# DISPC register map
Vendor: Texas Instruments
Peripheral module from a debugger description file (folder omap5430_ES2_PUBLIC).
Registers are 32-bit, access per field, reset 0x0 unless marked. A register's access mark holds for its fields unless they carry their own. Offsets are as the file gives them; lines under a group give offsets from that group; [hi:lo] are bit positions; {n}, {i} and the like mark numbered series; 'fields as' and 'values as' point back to an identical list; <NAME> marks a mode.

## DISPC (part 1 of 7)
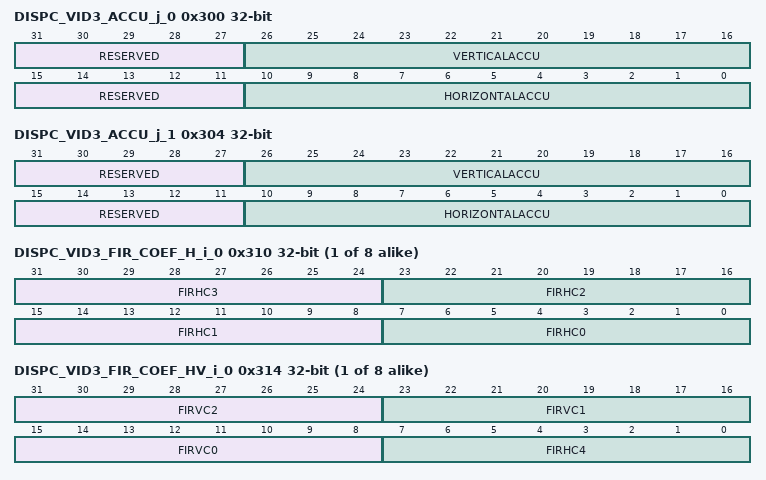
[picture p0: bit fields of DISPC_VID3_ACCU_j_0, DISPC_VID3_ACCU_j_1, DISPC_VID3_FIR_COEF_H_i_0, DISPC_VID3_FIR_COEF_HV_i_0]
0x300 DISPC_VID3_ACCU_j_0 — The register configures the resize accumulator init values for horizontal and vertical up/downsampling of the video window 3 (DISPC_VID3_ACCU_0 and DISPC_VID3_ACCU_1 for ping-pong mechanism with external trigger, based on the field polarity). It is used for ARGB and Y setting. Shadow register, updated on VFP start period of primary LCD or VFP start period of the secondary LCD or VFP start period of the third LCD or EVSYNC or when.GOWB is set to 1 by software and current WB frame is finished (no more data in the write-back pipeline). The synchronization event is defined based on the output using the pipeline: primary LCD, secondary LCD, third LCD, TV output or write-back to the memory
  [31:27] RESERVED ro — Write 0s for future compatibility. Reads return 0.
  [26:16] VERTICALACCU rw — Vertical initialization accu value Encoded value (from –1024 to 1023).
  [15:11] RESERVED ro — Write 0s for future compatibility. Reads return 0.
  [10:0] HORIZONTALACCU rw — Horizontal initialization accu value Encoded value (from –1024 to 1023).
0x304 DISPC_VID3_ACCU_j_1 — The register configures the resize accumulator init values for horizontal and vertical up/downsampling of the video window 3 (DISPC_VID3_ACCU_0 and DISPC_VID3_ACCU_1 for ping-pong mechanism with external trigger, based on the field polarity). It is used for ARGB and Y setting. Shadow register, updated on VFP start period of primary LCD or VFP start period of the secondary LCD or VFP start period of the third LCD or EVSYNC or when.GOWB is set to 1 by software and current WB frame is finished (no more data in the write-back pipeline). The synchronization event is defined based on the output using the pipeline: primary LCD, secondary LCD, third LCD, TV output or write-back to the memory
  fields as DISPC_VID3_ACCU_j_0
0x308 DISPC_VID3_BA_j_0 rw — The register configures the base address of the video buffer for the video window 3 (DISPC_VID3_BA_0 and DISPC_VID3_BA_1 for ping-pong mechanism with external trigger, based on the field polarity otherwise only DISPC_VID3_BA_0 is used)). Shadow register, updated on VFP start period of primary LCD or VFP start period of the secondary LCD or VFP start period of the third LCD or EVSYNC or when.GOWB is set to 1 by software and current WB frame is finished (no more data in the write-back pipeline). The synchronization event is defined based on the output using the pipeline: primary LCD, secondary LCD, third LCD, TV output or write-back to the memory
  [31:0] BA — Video base address Base address of the video buffer (aligned on pixel size boundary except in case of RGB24 packed format, 4-pixel alignment is required; in case of YUV4:2:2, 2-pixel alignment is required, and YUV4:2:0, byte alignment is supported)). It case of YUV4:2:0 format, it indicates the base address of the Y buffer. When the TILER is addressed, the bits: [28:27] = 0x0 for 8-bit tiled [28:27] = 0x1 for 16-bit tiled [28:27] = 0x2 for 32-bit tiled [28:27] = 0x3 for page mode [31:29] = 0x0 for 0-degree view [31:29] = 0x1 for 180-degree view + mirroring [31:29] = 0x2 for 0-degree view + mirroring [31:29] = 0x3 for 180-degree view [31:29] = 0x4 for 270-degree view + mirroring [31:29] = 0x5 for 270-degree view [31:29] = 0x6 for 90-degree view [31:29] = 0x7 for 90-degree view + mirroring Otherwise the bits indicated the corresponding bit address to access the SDRAM.
0x30C DISPC_VID3_BA_j_1 rw — The register configures the base address of the video buffer for the video window 3 (DISPC_VID3_BA_0 and DISPC_VID3_BA_1 for ping-pong mechanism with external trigger, based on the field polarity otherwise only DISPC_VID3_BA_0 is used)). Shadow register, updated on VFP start period of primary LCD or VFP start period of the secondary LCD or VFP start period of the third LCD or EVSYNC or when.GOWB is set to 1 by software and current WB frame is finished (no more data in the write-back pipeline). The synchronization event is defined based on the output using the pipeline: primary LCD, secondary LCD, third LCD, TV output or write-back to the memory
  fields as DISPC_VID3_BA_j_0
{0x310+8i} DISPC_VID3_FIR_COEF_H_i_{i} rw (i=0..7) — The bank of registers configure the up/down-scaling coefficients for the horizontal resize of the video picture associated with the video window 3 for the phases from 0 to 7. It is used for ARGB and Y setting. Shadow register, updated on VFP start period of primary LCD or VFP start period of the secondary LCD or VFP start period of the third LCD or EVSYNC or when.GOWB is set to 1 by software and current WB frame is finished (no more data in the write-back pipeline). The synchronization event is defined based on the output using the pipeline: primary LCD, secondary LCD, third LCD, TV output or write-back to the memory
  [31:24] FIRHC3 — Signed coefficient C3 for the horizontal up/down-scaling with the phase n
  [23:16] FIRHC2 — Unsigned coefficient C2 for the horizontal up/down-scaling with the phase n
  [15:8] FIRHC1 — Signed coefficient C1 for the horizontal up/down-scaling with the phase n
  [7:0] FIRHC0 — Signed coefficient C0 for the horizontal up/down-scaling with the phase n
{0x314+8i} DISPC_VID3_FIR_COEF_HV_i_{i} rw (i=0..7) — The bank of registers configure the down/up/down-scaling coefficients for the vertical and horizontal resize of the video picture associated with the video window 3 for the phases from 0 to 7. It is used for ARGB and Y setting. Shadow register, updated on VFP start period of primary LCD or VFP start period of the secondary LCD or VFP start period of the third LCD or EVSYNC or when.GOWB is set to 1 by software and current WB frame is finished (no more data in the write-back pipeline). The synchronization event is defined based on the output using the pipeline: primary LCD, secondary LCD, third LCD, TV output or write-back to the memory
  [31:24] FIRVC2 — Signed coefficient C2 for the vertical up/down-scaling with the phase n
  [23:16] FIRVC1 — Unsigned coefficient C1 for the vertical up/down-scaling with the phase n
  [15:8] FIRVC0 — Signed coefficient C0 for the vertical up/down-scaling with the phase n
  [7:0] FIRHC4 — Signed coefficient C4 for the horizontal up/down-scaling with the phase n
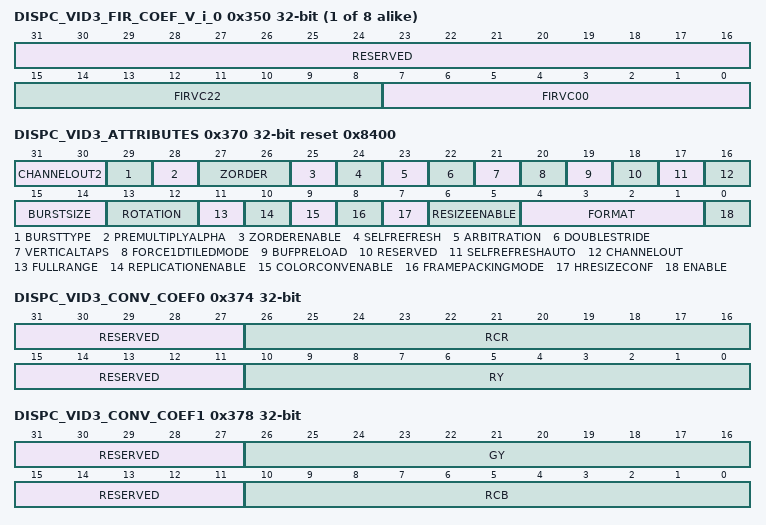
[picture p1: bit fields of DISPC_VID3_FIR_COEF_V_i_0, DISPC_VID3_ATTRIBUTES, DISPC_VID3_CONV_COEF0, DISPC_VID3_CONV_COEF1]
{0x350+4i} DISPC_VID3_FIR_COEF_V_i_{i} (i=0..7) — The bank of registers configure the down/up/down-scaling coefficients for the vertical resize of the video picture associated with the video window 3 for the phases from 0 to 7. It is used for ARGB and Y setting. Shadow register, updated on VFP start period of primary LCD or VFP start period of the secondary LCD or VFP start period of the third LCD or EVSYNC or when.GOWB is set to 1 by software and current WB frame is finished (no more data in the write-back pipeline). The synchronization event is defined based on the output using the pipeline: primary LCD, secondary LCD, third LCD, TV output or write-back to the memory
  [31:16] RESERVED ro — Write 0s for future compatibility. Reads return 0.
  [15:8] FIRVC22 rw — Signed coefficient C22 for the vertical up/down-scaling with the phase n
  [7:0] FIRVC00 rw — Signed coefficient C00 for the vertical up/down-scaling with the phase n
0x370 DISPC_VID3_ATTRIBUTES reset 0x8400 — The register configures the attributes of the video window 3. Shadow register, updated on VFP start period of primary LCD or VFP start period of the secondary LCD or VFP start period of the third LCD or EVSYNC or when.GOWB is set to 1 by software and current WB frame is finished (no more data in the write-back pipeline). The synchronization event is defined based on the output using the pipeline: primary LCD, secondary LCD, third LCD, TV output or write-back to the memory
  [31:30] CHANNELOUT2 rw — It is not used if CHANNELOUT is set to TV. Reserved when CHANNELOUT = 1 (should be set to zero) wr: immediate
    0=PrimaryLCDSel (Primary LCD output selected.); 1=SecondaryLCDSel (Secondary LCD output selected.); 2=ThirdLCDSel (Third LCD output selected.); 3=WriteBacksel (Write-back output to the memory selected.)
  [29] BURSTTYPE rw — The type of burst can be INCR (incremental) or BLCK (2D block). The 2D block is required when the TILER is targeted by the DMA engine.
    0=INC (INC burst type is used.); 1=BLCK (2D block burst type is used.)
  [28] PREMULTIPLYALPHA rw — The field configures the DISPC VID3 to process incoming data as premultiplied alpha data or non premultiplied alpha data. Default setting is non premultiplied alpha data.
    0=PremultipliedAlpha (Non premultiplyalpha data color component); 1=PremultipliedAlpha (Premultiplyalpha data color component)
  [27:26] ZORDER rw — Z-Order defining the priority of the layer compared to others when overlaying. It is software responsibility to ensure that each layer connected to the same overlay manager has a different z-order value. If bit 25 is set to 0, the ZORDER bit field is ignored and replaced by the value 0.
    0=Z-order 0: layer above solid background color and below layer with higher Z-order values; 1=Z-order 1: layer above layer with z-order value of 0 and below layers with z-order values of 2 and 3; 3=Z-order 3: layer above all the other layers; 2=Z-order 2: layer above layers with z-order value of 0 and 1 and below layer with z-order value of 3
  [25] ZORDERENABLE rw — Z-order Enable. The bit field ZORDER is used only when the Z-order is enabled.
    0=Z-order disabled. The Z-order of the layer is 0.; 1=ZorderEnb (Z-order enabled. The Z-order is defined by the bit field ZORDER (bits 26 and 27).)
  [24] SELFREFRESH rw — Enables the self refresh of the video window from its own DMA buffer only.
    0=SelfRefreshDis (The video pipeline accesses the interconnect to fetch data from the system memory.); 1=SelfRefreshEnb (The video pipeline does not need anymore to fetch data from memory. Only the DMA buffer associated with the video3 is used. It takes effect after the frame has been loaded in the DMA buffer.)
  [23] ARBITRATION rw — Determines the priority of the video pipeline. The video pipeline is one of the high priority pipeline. The arbitration gives always the priority first to the high priority pipelines using round-robin between them. When there is only normal priority pipelines sending requests, the round-robin applies between them.
    0=NormalPrio (The video pipeline is one of the normal priority pipeline.); 1=HighPrio (The video pipeline is one of the high priority pipeline.)
  [22] DOUBLESTRIDE rw — Determines if the stride for CbCr buffer is the 1x or 2x of the Y buffer stride. It is only used in case of YUV4:2:0.
    0=Initial (The CbCr stride value is equal to the Y stride.); 1=Double (The CbCr stride value is double to the Y stride.)
  [21] VERTICALTAPS rw — Video vertical resize tap number
    0=taps3 (3 taps are used for the vertical filtering logic. The 2 other taps are not used. The associated bit fields for the 2 other taps coefficients do not need to be initialized.); 1=taps5 (5 taps are used for the vertical filtering logic.)
  [20] FORCE1DTILEDMODE rw — Force TILED regions access to 1D or 2D.
    0=TiledRegions2DAccess (2D accesses for tiled regions); 1=TiledRegions1DAccess (1D accesses for tiled regions)
  [19] BUFPRELOAD rw — Video Preload Value
    0=DefVal (Hardware prefetches pixels up to the preload value defined in the preload register); 1=HighThres (Hardware prefetches pixels up to high threshold value)
  [18] RESERVED ro — Write 0s for future compatibility. Reads return 0.
  [17] SELFREFRESHAUTO rw — Automatic self-refresh mode
    0=SelfRefreshAutoDis (The transition from SELFREFRESH disabled to enabled is controlled by SW.); 1=SelfrefreshAutoEn (The transition from SELFREFRESH disabled to enabled is controlled only by hardware.)
  [16] CHANNELOUT rw — Video channel out configuration: LCD, WB or TV. wr: immediate
    0=LCDOp (LCD output or WB to the memory selected. bit fields 31 and 30 defines the output associated (primary, secondary or write-back).); 1=TVOp (TV output selected)
  [15:14] BURSTSIZE rw — Video DMA burst size
    0=Burst2x128b (2 × 128-bit bursts); 1=Burst4x128b (4 × 128-bit bursts); 2=Burst8x128b (8 × 128-bit bursts)
  [13:12] ROTATION rw — Video rotation flag
    0=No rotation; 1=Rot90 (Rotation by 90 degrees); 3=Rot270 (Rotation by 270 degrees); 2=Rot180 (Rotation by 180 degrees)
  [11] FULLRANGE rw — Color Space Conversion full range setting.
    0=Limrange (Limited range selected: 16 subtracted from Y before color space conversion); 1=Full range selected: Y is not modified before the color space conversion
  [10] REPLICATIONENABLE rw
    0=VRepLDis (Disable Video replication logic); 1=VRepLEnb (Enable Video replication logic)
  [9] COLORCONVENABLE rw — Enable the color space conversion. The hardware does not enable/disable the conversion based on the pixel format. The bit field shall be reset when the format is not YUV.
    0=ColSpCDis (Disable Color Space Conversion YUV to RGB); 1=ColSpCEnb (Enable Color Space Conversion YUV to RGB)
  [8] FRAMEPACKINGMODE rw — Frame packing mode control.
    0=FPMDis (Frame Packing mode is disabled); 1=FPMEnb (Nibble mode is enabled)
  [7] HRESIZECONF ro — Write 0s for future compatibility. Reads return 0.
  [6:5] RESIZEENABLE rw — Video resize enable
    0=ReSizeProc (Disable both horizontal and vertical resize processing); 1=HReSize (Enable the horizontal resize processing); 3=HVReSize (Enable both horizontal and vertical resize processing); 2=VReSize (Enable the vertical resize processing)
  [4:1] FORMAT rw — Video format. It defines the pixel format when fetching the video 3 picture into memory.
    6=RGB16 (RGB16-565); 1=RGBx12 (RGB12x-4444); 10=YUV2 (YUV2 4:2:2 co-sited); 7=ARGB16_1 (ARGB16-1555); 13=RGBA32 (RGBA32-8888); 0=NV12 (NV12 4:2:0 2 buffers (Y + UV)); 2=RGBA12 (RGBA12-4444); 8=xRGB24 (RGB24-8888 (32-bit container)); 9=RGB24 (RGB24-888 (24-bit container)); 11=UYVY (UYVY 4:2:2 co-sited); 5=ARGB16 (ARGB16-4444); 15=xRGB15-1555; 12=ARGB32 (ARGB32-8888); 4=xRGB12-4444; 3=BGRA32 (BGRA32-8888); 14=xRGB12 (RGBx24-8888 (24-bit RGB aligned on MSB of the 32-bit container))
  [0] ENABLE rw — Video Enable
    0=Video disabled (video pipeline inactive and window not present); 1=VideoEnb (Video enabled (video pipeline active and window present on the screen))
0x374 DISPC_VID3_CONV_COEF0 — The register configures the color space conversion matrix coefficients for the video pipeline 3. Shadow register, updated on VFP start period of primary LCD or VFP start period of the secondary LCD or VFP start period of the third LCD or EVSYNC or when.GOWB is set to 1 by software and current WB frame is finished (no more data in the write-back pipeline). The synchronization event is defined based on the output using the pipeline: primary LCD, secondary LCD, third LCD, TV output or write-back to the memory
  [31:27] RESERVED ro — Write 0s for future compatibility. Reads return 0.
  [26:16] RCR rw — RCr coefficient encoded signed value (from –1024 to 1023).
  [15:11] RESERVED ro — Write 0s for future compatibility. Reads return 0.
  [10:0] RY rw — RY coefficient encoded signed value (from –1024 to 1023).
0x378 DISPC_VID3_CONV_COEF1 — The register configures the color space conversion matrix coefficients for the video pipeline 3. Shadow register, updated on VFP start period of primary LCD or VFP start period of the secondary LCD or VFP start period of the third LCD or EVSYNC or when.GOWB is set to 1 by software and current WB frame is finished (no more data in the write-back pipeline). The synchronization event is defined based on the output using the pipeline: primary LCD, secondary LCD, third LCD, TV output or write-back to the memory
  [31:27] RESERVED ro — Write 0s for future compatibility. Reads return 0.
  [26:16] GY rw — GY coefficient encoded signed value (from –1024 to 1023).
  [15:11] RESERVED ro — Write 0s for future compatibility. Reads return 0.
  [10:0] RCB rw — RCb coefficient encoded signed value (from –1024 to 1023).
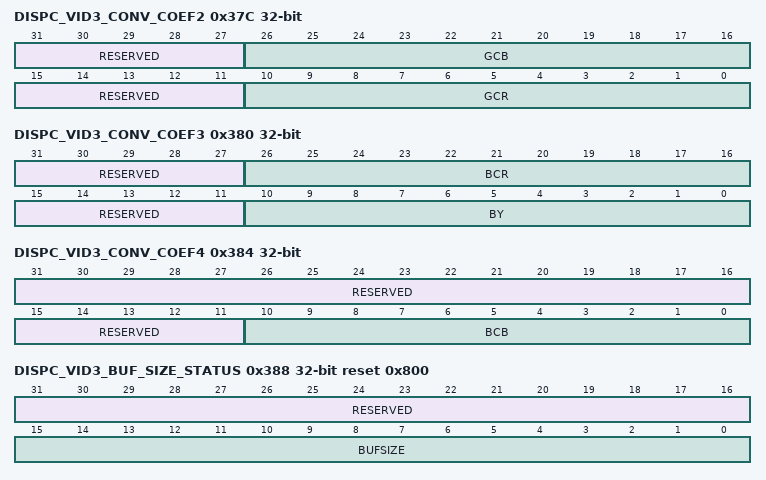
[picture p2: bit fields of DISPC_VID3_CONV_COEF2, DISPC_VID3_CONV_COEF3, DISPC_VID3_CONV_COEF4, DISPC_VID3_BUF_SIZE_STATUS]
0x37C DISPC_VID3_CONV_COEF2 — The register configures the color space conversion matrix coefficients for the video pipeline 3. Shadow register, updated on VFP start period of primary LCD or VFP start period of the secondary LCD or VFP start period of the third LCD or EVSYNC or when.GOWB is set to 1 by software and current WB frame is finished (no more data in the write-back pipeline). The synchronization event is defined based on the output using the pipeline: primary LCD, secondary LCD, third LCD, TV output or write-back to the memory
  [31:27] RESERVED ro — Write 0s for future compatibility. Reads return 0.
  [26:16] GCB rw — GCb coefficient encoded signed value (from –1024 to 1023).
  [15:11] RESERVED ro — Write 0s for future compatibility. Reads return 0.
  [10:0] GCR rw — GCr coefficient encoded signed value (from –1024 to 1023).
0x380 DISPC_VID3_CONV_COEF3 — The register configures the color space conversion matrix coefficients for the video pipeline 3. Shadow register, updated on VFP start period of primary LCD or VFP start period of the secondary LCD or VFP start period of the third LCD or EVSYNC or when.GOWB is set to 1 by software and current WB frame is finished (no more data in the write-back pipeline). The synchronization event is defined based on the output using the pipeline: primary LCD, secondary LCD, third LCD, TV output or write-back to the memory
  [31:27] RESERVED ro — Write 0s for future compatibility. Reads return 0.
  [26:16] BCR rw — BCr coefficient encoded signed value (from –1024 to 1023).
  [15:11] RESERVED ro — Write 0s for future compatibility. Reads return 0.
  [10:0] BY rw — BY coefficient encoded signed value (from –1024 to 1023).
0x384 DISPC_VID3_CONV_COEF4 — The register configures the color space conversion matrix coefficients for the video pipeline 3. Shadow register, updated on VFP start period of primary LCD or VFP start period of the secondary LCD or VFP start period of the third LCD or EVSYNC or when.GOWB is set to 1 by software and current WB frame is finished (no more data in the write-back pipeline). The synchronization event is defined based on the output using the pipeline: primary LCD, secondary LCD, third LCD, TV output or write-back to the memory
  [31:11] RESERVED ro — Write 0s for future compatibility. Reads return 0.
  [10:0] BCB rw — BCb coefficient encoded signed value (from –1024 to 1023).
0x388 DISPC_VID3_BUF_SIZE_STATUS ro reset 0x800 — The register defines the DMA buffer size for the video pipeline 3.
  [31:16] RESERVED — Write 0s for future compatibility. Reads return 0.
  [15:0] BUFSIZE — DMA buffer Size in number of 128 bits.
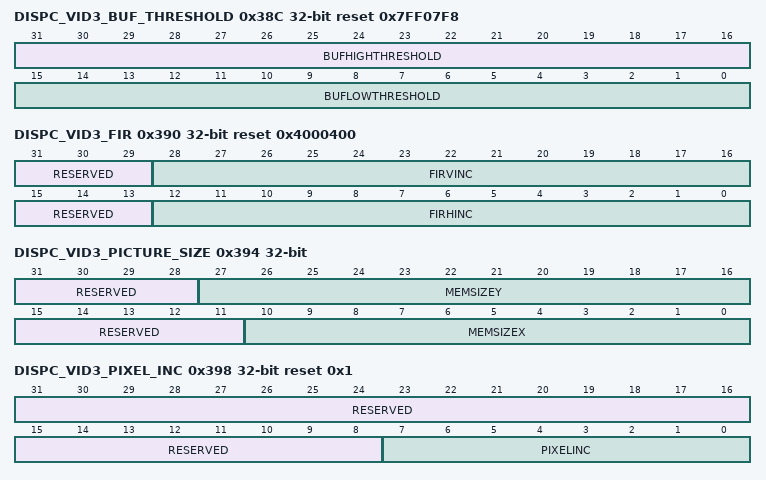
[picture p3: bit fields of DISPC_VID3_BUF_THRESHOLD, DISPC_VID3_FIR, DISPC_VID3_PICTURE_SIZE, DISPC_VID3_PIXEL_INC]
0x38C DISPC_VID3_BUF_THRESHOLD rw reset 0x7FF07F8 — The register configures the DMA buffer associated with the video pipeline 3. Shadow register, updated on VFP start period of primary LCD or VFP start period of the secondary LCD or VFP start period of the third LCD or EVSYNC or when.GOWB is set to 1 by software and current WB frame is finished (no more data in the write-back pipeline). The synchronization event is defined based on the output using the pipeline: primary LCD, secondary LCD, third LCD, TV output or write-back to the memory
  [31:16] BUFHIGHTHRESHOLD — DMA buffer high threshold number of 128 bits defining the threshold value
  [15:0] BUFLOWTHRESHOLD — DMA buffer low threshold number of 128 bits defining the threshold value
0x390 DISPC_VID3_FIR reset 0x4000400 — The register configures the resize factors for horizontal and vertical up/downsampling of the video window 3. It is used for ARGB and Y setting. Shadow register, updated on VFP start period of primary LCD or VFP start period of the secondary LCD or VFP start period of the third LCD or EVSYNC or when.GOWB is set to 1 by software and current WB frame is finished (no more data in the write-back pipeline). The synchronization event is defined based on the output using the pipeline: primary LCD, secondary LCD, third LCD, TV output or write-back to the memory
  [31:29] RESERVED ro — Write 0s for future compatibility. Reads return 0.
  [28:16] FIRVINC rw — Vertical increment of the up/downsampling filter Encoded value (from 1 to 4096). The value 0 is invalid. The values greater than 4096 are invalid.
  [15:13] RESERVED ro — Write 0s for future compatibility. Reads return 0.
  [12:0] FIRHINC rw — Horizontal increment of the up/downsampling filter Encoded value (from 1 to 4096). The value 0 is invalid. The values greater than 4096 are invalid.
0x394 DISPC_VID3_PICTURE_SIZE — The register configures the size of the video picture associated with the video layer 3 before up/down-scaling. Shadow register, updated on VFP start period of primary LCD or VFP start period of the secondary LCD or VFP start period of the third LCD or EVSYNC or when.GOWB is set to 1 by software and current WB frame is finished (no more data in the write-back pipeline). The synchronization event is defined based on the output using the pipeline: primary LCD, secondary LCD, third LCD, TV output or write-back to the memory
  [31:28] RESERVED ro — Write 0s for future compatibility. Reads return 0.
  [27:16] MEMSIZEY rw — Number of lines of the video picture Encoded value (from 1 to 4096) to specify the number of lines of the video picture in memory (program to value minus 1). When predecimation is set, the value represents the size of the image after predecimation but the max size of the unpredecimated image size in memory is still bounded 2.
  [15:11] RESERVED ro — Write 0s for future compatibility. Reads return 0.
  [10:0] MEMSIZEX rw — Number of pixels of the video picture Encoded value (from 1 to 2048) to specify the number of pixels of the video picture in memory (program to value minus 1). The size is limited to the size of the line buffer of the vertical sampling block in case the video picture is processed by the vertical filtering unit. (program to value minus 1). When predecimation is set, the value represents the size of the image after predecimation but the max size of the unpredecimated image size in memory is still bounded 2.
0x398 DISPC_VID3_PIXEL_INC reset 0x1 — The register configures the number of bytes to increment between two pixels for the buffer associated with the video window 3. For more information, see, Predecimation.The register is used only when the TILER is not present in the system in order to perform low performance rotation. When the TILER IP is present it is highly recommended to use it for performing the rotation. Shadow register, updated on VFP start period of primary LCD or VFP start period of the secondary LCD or VFP start period of the third LCD or EVSYNC or when .GOWB is set to 1 by software and current WB frame is finished (no more data in the write-back pipeline). The synchronization event is defined based on the output using the pipeline: primary LCD, secondary LCD, third LCD, TV output or write-back to the memory
  [31:8] RESERVED ro — Write 0s for future compatibility. Reads return 0.
  [7:0] PIXELINC rw — Number of bytes to increment between two pixels. Encoded unsigned value (from 1 to 255) to specify the number of bytes between two pixels in the video buffer. The value 0 is invalid. The value 1 means next pixel. The value 1 + n * bpp means increment of n pixels. For YUV4:2:0, maximum supported value is 128.
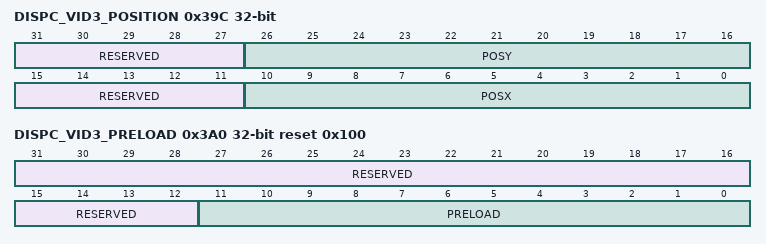
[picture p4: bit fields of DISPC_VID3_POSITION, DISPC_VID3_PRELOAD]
0x39C DISPC_VID3_POSITION — The register configures the position of the video window 3. Shadow register, updated on VFP start period of primary LCD or VFP start period of the secondary LCD or VFP start period of the third LCD or EVSYNC or when.GOWB is set to 1 by software and current WB frame is finished (no more data in the write-back pipeline). The synchronization event is defined based on the output using the pipeline: primary LCD, secondary LCD, third LCD, TV output or write-back to the memory
  [31:27] RESERVED ro — Write 0s for future compatibility. Reads return 0.
  [26:16] POSY rw — Y position of the video window 2 Encoded value (from 0 to 2047) to specify the Y position of the video window 2 .The line at the top has the Y-position 0.
  [15:11] RESERVED ro — Write 0s for future compatibility. Reads return 0.
  [10:0] POSX rw — X position of the video window 2 Encoded value (from 0 to 2047) to specify the X position of the video window 2. The first pixel on the left of the display screen has the X-position 0.
0x3A0 DISPC_VID3_PRELOAD reset 0x100 — The register configures the DMA buffer of the video 3 pipeline. Shadow register, updated on VFP start period of primary LCD or VFP start period of the secondary LCD or VFP start period of the third LCD or EVSYNC or when.GOWB is set to 1 by software and current WB frame is finished (no more data in the write-back pipeline). The synchronization event is defined based on the output using the pipeline: primary LCD, secondary LCD, third LCD, TV output or write-back to the memory
  [31:12] RESERVED ro — Write 0s for future compatibility. Reads return 0.
  [11:0] PRELOAD rw — DMA buffer preload value Number of 128-bit words defining the preload value.
